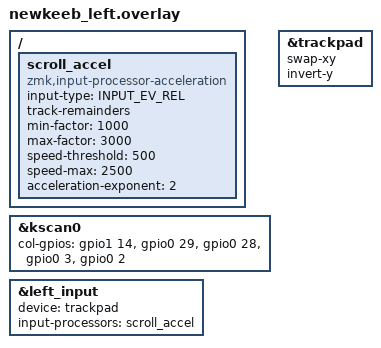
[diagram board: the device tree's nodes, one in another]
/*
 * LEFT half = split PERIPHERAL (forced ROLE_CENTRAL=n in build.yaml).
 * Local trackpad -> SCROLL, forwarded to the dongle. Keeps col-offset 0 (cols 0-4).
 */

#include "newkeeb_half.dtsi"
#include <zephyr/dt-bindings/input/input-event-codes.h>

/*
 * Scroll acceleration, applied HERE on the peripheral (accurate local timing).
 * The accel module only works on REL_X/REL_Y, so we accelerate the raw finger
 * motion before forwarding; the dongle then maps that to a wheel. Fast swipe =
 * faster scroll. Same curve math as the pointer.
 */
/ {
    scroll_accel: scroll_accel {
        compatible = "zmk,input-processor-acceleration";
        #input-processor-cells = <0>;
        input-type = <INPUT_EV_REL>;
        track-remainders;
        min-factor = <1000>;   /* 1.0x slow (don't slow scroll below normal) */
        max-factor = <3000>;   /* 3.0x fast swipe */
        speed-threshold = <500>;
        speed-max = <2500>;
        acceleration-exponent = <2>;
    };
};

/*
 * Column order fix: the left half was wired with its columns in the opposite
 * order from what the shared kscan assumes, so keys came out mirrored. Reverse
 * the left's column scan order here (same reversed order the right uses).
 */
&kscan0 {
    col-gpios
        = <&gpio1 14 GPIO_ACTIVE_HIGH>   /* D9  P1.14 -> logical col0 */
        , <&gpio0 29 GPIO_ACTIVE_HIGH>   /* D3  P0.29 -> logical col1 */
        , <&gpio0 28 GPIO_ACTIVE_HIGH>   /* D2  P0.28 -> logical col2 */
        , <&gpio0  3 GPIO_ACTIVE_HIGH>   /* D1  P0.03 -> logical col3 */
        , <&gpio0  2 GPIO_ACTIVE_HIGH>   /* D0  P0.02 -> logical col4 */
        ;
};

/* Forward this half's pad to the scroll proxy, accelerated here first. */
&left_input {
    status = "okay";
    device = <&trackpad>;
    input-processors = <&scroll_accel>;
};

/*
 * Axis orientation for the LEFT pad (SCROLL).
 * Enables vertical scroll on Up/Down swipe and horizontal scroll on Left/Right swipe.
 */
&trackpad {
    swap-xy;
    invert-y;
};
